# STM32H573 register map
File version: 1.7
CPU: CM33 r0p0, little endian, MPU, FPU, 4 interrupt priority bits
Registers are 32-bit, read-write, reset 0x0 unless marked. A register's access mark holds for its fields unless they carry their own. Offsets are from the block's base; [hi:lo] are bit positions; {n}, {i} and the like mark numbered series; 'fields as' and 'values as' point back to an identical list.

## TIM2 — General-purpose timers
Base 0x40000000
Same registers: SEC_TIM2 0x50000000
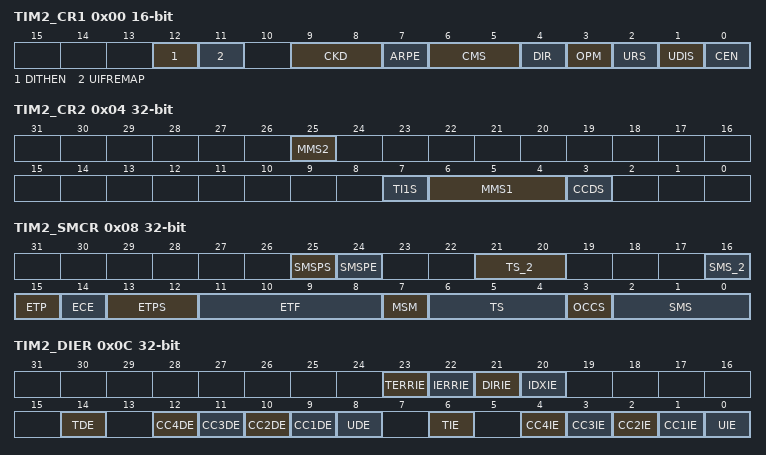
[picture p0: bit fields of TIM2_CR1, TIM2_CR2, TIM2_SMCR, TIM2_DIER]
0x00 TIM2_CR1 16-bit — TIM2 control register 1
  [12] DITHEN — Dithering Enable Note: The DITHEN bit can only be modified when CEN bit is reset.
    0=Dithering disabled; 1=Dithering enabled
  [11] UIFREMAP — UIF status bit remapping
    0=No remapping. UIF status bit is not copied to TIMx_CNT register bit 31.; 1=Remapping enabled. UIF status bit is copied to TIMx_CNT register bit 31.
  [9:8] CKD — Clock division This bit-field indicates the division ratio between the timer clock (tim_ker_ck) frequency and sampling clock used by the digital filters (tim_etr_in, tim_tix),
    0=tDTS = ttim_ker_ck; 1=tDTS = 2 ttim_ker_ck; 2=tDTS = 4 ttim_ker_ck
  [7] ARPE — Auto-reload preload enable
    0=TIMx_ARR register is not buffered; 1=TIMx_ARR register is buffered
  [6:5] CMS — Center-aligned mode selection Note: It is not allowed to switch from edge-aligned mode to center-aligned mode as long as the counter is enabled (CEN=1)
    0=Edge-aligned mode. The counter counts up or down depending on the direction bit (DIR).; 1=Center-aligned mode 1. The counter counts up and down alternatively. Output compare interrupt flags of channels configured in output (CCxS=00 in TIMx_CCMRx register) are set only when the counter is counting down.; 2=Center-aligned mode 2. The counter counts up and down alternatively. Output compare interrupt flags of channels configured in output (CCxS=00 in TIMx_CCMRx register) are set only when the counter is counting up.; 3=Center-aligned mode 3. The counter counts up and down alternatively. Output compare interrupt flags of channels configured in output (CCxS=00 in TIMx_CCMRx register) are set both when the counter is counting up or down.
  [4] DIR — Direction Note: This bit is read only when the timer is configured in Center-aligned mode or Encoder mode.
    0=Counter used as upcounter; 1=Counter used as downcounter
  [3] OPM — One-pulse mode
    0=Counter is not stopped at update event; 1=Counter stops counting at the next update event (clearing the bit CEN)
  [2] URS — Update request source This bit is set and cleared by software to select the UEV event sources. Counter overflow/underflow Setting the UG bit Update generation through the slave mode controller
    0=Any of the following events generate an update interrupt or DMA request if enabled. These events can be:; 1=Only counter overflow/underflow generates an update interrupt or DMA request if enabled
  [1] UDIS — Update disable This bit is set and cleared by software to enable/disable UEV event generation. Counter overflow/underflow Setting the UG bit Update generation through the slave mode controller Buffered registers are then loaded with their preload values.
    0=UEV enabled. The Update (UEV) event is generated by one of the following events:; 1=UEV disabled. The Update event is not generated, shadow registers keep their value (ARR, PSC, CCRx). However the counter and the prescaler are reinitialized if the UG bit is set or if a hardware reset is received from the slave mode controller.
  [0] CEN — Counter enable Note: External clock, gated mode and encoder mode can work only if the CEN bit has been previously set by software. However trigger mode can set the CEN bit automatically by hardware. CEN is cleared automatically in one-pulse mode, when an update event occurs.
    0=Counter disabled; 1=Counter enabled
0x04 TIM2_CR2 — TIM2 control register 2
  [25] MMS2 — Master mode selection These bits allow to select the information to be sent in master mode to slave timers for synchronization (tim_trgo). The combination is as follows: tim_trgo, except if the master/slave mode is selected (see the MSM bit description in TIMx_SMCR register). Others: Reserved Note: The clock of the slave timer or ADC must be enabled prior to receive events from the master timer, and must not be changed on-the-fly while triggers are received from the master timer.
    0=Reset the UG bit from the TIMx_EGR register is used as trigger output (tim_trgo). If the reset is generated by the trigger input (slave mode controller configured in reset mode) then the signal on tim_trgo is delayed compared to the actual reset.; 1=Enable the Counter enable signal, CNT_EN, is used as trigger output (tim_trgo). It is useful to start several timers at the same time or to control a window in which a slave timer is enabled. The Counter Enable signal is generated by a logic AND between CEN control bit and the trigger input when configured in gated mode.When the Counter Enable signal is controlled by the trigger input, there is a delay on
  [7] TI1S — tim_ti1 selection
    0=The tim_ti1_in[15..0] multiplexer output is to tim_ti1 input; 1=The tim_ti1_in[15..0], tim_ti2_in[15..0] and tim_ti3_in[15..0] multiplexers outputs are XORed and connected to the tim_ti1 input. See also sensors on page 1494.
  [6:4] MMS1 — Master mode selection These bits allow to select the information to be sent in master mode to slave timers for synchronization (tim_trgo). The combination is as follows: tim_trgo, except if the master/slave mode is selected (see the MSM bit description in TIMx_SMCR register). Others: Reserved Note: The clock of the slave timer or ADC must be enabled prior to receive events from the master timer, and must not be changed on-the-fly while triggers are received from the master timer.
    0=Reset the UG bit from the TIMx_EGR register is used as trigger output (tim_trgo). If the reset is generated by the trigger input (slave mode controller configured in reset mode) then the signal on tim_trgo is delayed compared to the actual reset.; 1=Enable the Counter enable signal, CNT_EN, is used as trigger output (tim_trgo). It is useful to start several timers at the same time or to control a window in which a slave timer is enabled. The Counter Enable signal is generated by a logic AND between CEN control bit and the trigger input when configured in gated mode.When the Counter Enable signal is controlled by the trigger input, there is a delay on; 2=Update The update event is selected as trigger output (tim_trgo). For instance a master timer can then be used as a prescaler for a slave timer.; 3=Compare Pulse The trigger output send a positive pulse when the CC1IF flag is to be set (even if it was already high), as soon as a capture or a compare match occurred (tim_trgo); {v}=Compare tim_oc{v-3}refc signal is used as trigger output (tim_trgo) (v=4..7)
  [3] CCDS — Capture/compare DMA selection
    0=CCx DMA request sent when CCx event occurs; 1=CCx DMA requests sent when update event occurs
0x08 TIM2_SMCR — TIM2 slave mode control register
  [25] SMSPS — SMS preload source This bit selects whether the events that triggers the SMS[3:0] bitfield transfer from preload to active
    0=The transfer is triggered by the Timer's Update event; 1=The transfer is triggered by the Index event
  [24] SMSPE — SMS preload enable This bit selects whether the SMS[3:0] bitfield is preloaded
    0=SMS[3:0] bitfield is not preloaded; 1=SMS[3:0] preload is enabled
  [21:20] TS_2 — Trigger selection (see bits 21:20 for TS[4:3]) This bit-field selects the trigger input to be used to synchronize the counter. Others: Reserved See for product specific implementation details. Note: These bits must be changed only when they are not used (e.g. when SMS=000) to avoid wrong edge detections at the transition.
    {v}=Internal trigger {v} (tim_itr{v}) (v=0..3)
  [16] SMS_2 — Slave mode selection When external signals are selected the active edge of the trigger signal (tim_trgi) is linked to the polarity selected on the external input (see Input Control register and Control Register description. Note: The gated mode must not be used if tim_ti1f_ed is selected as the trigger input (TS=00100). Indeed, tim_ti1f_ed outputs 1 pulse for each transition on tim_ti1f, whereas the gated mode checks the level of the trigger signal. Note: The clock of the slave peripherals (timer, ADC, ...) receiving the tim_trgo signal must be enabled prior to receive events from the master timer, and the clock frequency (prescaler) must not be changed on-the-fly while triggers are received from the master timer.
    0=Slave mode disabled if CEN = '1 then the prescaler is clocked directly by the internal clock; 1=Encoder mode 1 Counter counts up/down on tim_ti1fp1 edge depending on tim_ti2fp2 level
  [15] ETP — External trigger polarity This bit selects whether tim_etr_in or tim_etr_in is used for trigger operations
    0=tim_etr_in is non-inverted, active at high level or rising edge; 1=tim_etr_in is inverted, active at low level or falling edge
  [14] ECE — External clock enable This bit enables External clock mode 2. Note: Setting the ECE bit has the same effect as selecting external clock mode 1 with tim_trgi connected to tim_etrf (SMS=111 and TS=00111). It is possible to simultaneously use external clock mode 2 with the following slave modes: reset mode, gated mode and trigger mode. Nevertheless, tim_trgi must not be connected to tim_etrf in this case (TS bits must not be 00111). If external clock mode 1 and external clock mode 2 are enabled at the same time, the external clock input is tim_etrf.
    0=External clock mode 2 disabled; 1=External clock mode 2 enabled. The counter is clocked by any active edge on the tim_etrf signal.
  [13:12] ETPS — External trigger prescaler External trigger signal tim_etrp frequency must be at most 1/4 of tim_ker_ck frequency. A prescaler can be enabled to reduce tim_etrp frequency. It is useful when inputting fast external clocks on tim_etr_in.
    0=Prescaler OFF; 1=tim_etrp frequency divided by 2; 2=tim_etrp frequency divided by 4; 3=tim_etrp frequency divided by 8
  [11:8] ETF — External trigger filter This bit-field then defines the frequency used to sample tim_etrp signal and the length of the digital filter applied to tim_etrp. The digital filter is made of an event counter in which N consecutive events are needed to validate a transition on the output:
    0=No filter, sampling is done at fDTS; 1=fSAMPLING=ftim_ker_ck, N=2; 2=fSAMPLING=ftim_ker_ck, N=4; 3=fSAMPLING=ftim_ker_ck, N=8; 4=fSAMPLING=fDTS/2, N=6; 5=fSAMPLING=fDTS/2, N=8; 6=fSAMPLING=fDTS/4, N=6; 7=fSAMPLING=fDTS/4, N=8; 8=fSAMPLING=fDTS/8, N=6; 9=fSAMPLING=fDTS/8, N=8; 10=fSAMPLING=fDTS/16, N=5; 11=fSAMPLING=fDTS/16, N=6; 12=fSAMPLING=fDTS/16, N=8; 13=fSAMPLING=fDTS/32, N=5; 14=fSAMPLING=fDTS/32, N=6; 15=fSAMPLING=fDTS/32, N=8
  [7] MSM — Master/Slave mode
    0=No action; 1=The effect of an event on the trigger input (tim_trgi) is delayed to allow a perfect synchronization between the current timer and its slaves (through tim_trgo). It is useful if we want to synchronize several timers on a single external event.
  [6:4] TS — Trigger selection (see bits 21:20 for TS[4:3]) This bit-field selects the trigger input to be used to synchronize the counter. Others: Reserved See for product specific implementation details. Note: These bits must be changed only when they are not used (e.g. when SMS=000) to avoid wrong edge detections at the transition.
    {v}=Internal trigger {v} (tim_itr{v}) (v=0..3); 4=tim_ti1 edge detector (tim_ti1f_ed); 5=Filtered timer input 1 (tim_ti1fp1); 6=Filtered timer input 2 (tim_ti2fp2); 7=External trigger input (tim_etrf)
  [3] OCCS — OCREF clear selection This bit is used to select the OCREF clear source Note: If the OCREF clear selection feature is not supported, this bit is reserved and forced by hardware to '0'. .
    0=tim_ocref_clr_int is connected to the tim_ocref_clr input; 1=tim_ocref_clr_int is connected to tim_etrf
  [2:0] SMS — Slave mode selection When external signals are selected the active edge of the trigger signal (tim_trgi) is linked to the polarity selected on the external input (see Input Control register and Control Register description. Note: The gated mode must not be used if tim_ti1f_ed is selected as the trigger input (TS=00100). Indeed, tim_ti1f_ed outputs 1 pulse for each transition on tim_ti1f, whereas the gated mode checks the level of the trigger signal. Note: The clock of the slave peripherals (timer, ADC, ...) receiving the tim_trgo signal must be enabled prior to receive events from the master timer, and the clock frequency (prescaler) must not be changed on-the-fly while triggers are received from the master timer.
    0=Slave mode disabled if CEN = '1 then the prescaler is clocked directly by the internal clock; 1=Encoder mode 1 Counter counts up/down on tim_ti1fp1 edge depending on tim_ti2fp2 level; 2=Encoder mode 2 Counter counts up/down on tim_ti2fp2 edge depending on tim_ti1fp1 level; 3=Encoder mode 3 Counter counts up/down on both tim_ti1fp1 and tim_ti2fp2 edges depending on the level of the other input; 4=Reset Mode Rising edge of the selected trigger input (tim_trgi) reinitializes the counter and generates an update of the registers; 5=Gated Mode The counter clock is enabled when the trigger input (tim_trgi) is high. The counter stops (but is not reset) as soon as the trigger becomes low. Both start and stop of the counter are controlled.; 6=Trigger Mode The counter starts at a rising edge of the trigger tim_trgi (but it is not reset). Only the start of the counter is controlled.; 7=External Clock Mode 1 Rising edges of the selected trigger (tim_trgi) clock the counter
0x0C TIM2_DIER — TIM2 DMA/Interrupt enable register
  [23] TERRIE — Transition error interrupt enable
    0=Transition error interrupt disabled; 1=Transition error interrupt enabled
  [22] IERRIE — Index error interrupt enable
    0=Index error interrupt disabled; 1=Index error interrupt enabled
  [21] DIRIE — Direction change interrupt enable
    0=Direction change interrupt disabled; 1=Direction change interrupt enabled
  [20] IDXIE — Index interrupt enable
    0=Index interrupt disabled; 1=Index interrupt enabled
  [14] TDE — Trigger DMA request enable
    0=Trigger DMA request disabled; 1=Trigger DMA request enabled
  [n+8] CC{n}DE (n=1..4) — Capture/Compare {n} DMA request enable
    0=CC{n} DMA request disabled; 1=CC{n} DMA request enabled
  [8] UDE — Update DMA request enable
    0=Update DMA request disabled; 1=Update DMA request enabled
  [6] TIE — Trigger interrupt enable
    0=Trigger interrupt disabled; 1=Trigger interrupt enabled
  [n] CC{n}IE (n=1..4) — Capture/Compare {n} interrupt enable
    0=CC{n} interrupt disabled; 1=CC{n} interrupt enabled
  [0] UIE — Update interrupt enable
    0=Update interrupt disabled; 1=Update interrupt enabled
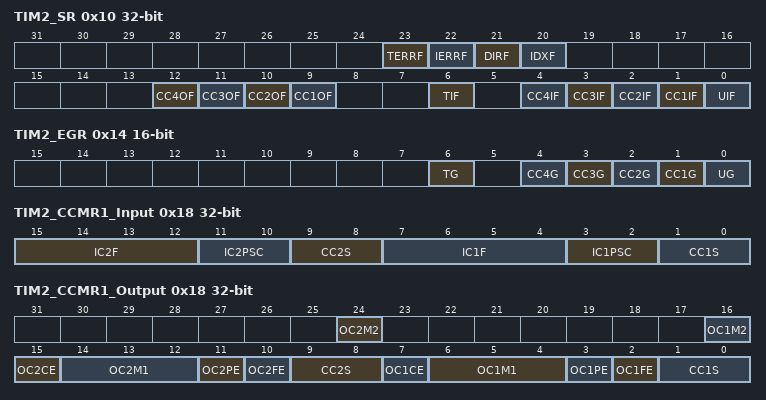
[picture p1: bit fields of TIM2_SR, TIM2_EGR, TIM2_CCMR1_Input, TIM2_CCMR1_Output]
0x10 TIM2_SR — TIM2 status register
  [23] TERRF — Transition error interrupt flag This flag is set by hardware when a transition error is detected in encoder mode. It is cleared by software by writing it to '0'.
    0=No encoder transition error has been detected; 1=An encoder transition error has been detected
  [22] IERRF — Index error interrupt flag This flag is set by hardware when an index error is detected. It is cleared by software by writing it to '0'.
    0=No index error has been detected; 1=An index error has been detected
  [21] DIRF — Direction change interrupt flag This flag is set by hardware when the direction changes in encoder mode (DIR bit value in TIMx_CR is changing). It is cleared by software by writing it to '0'.
    0=No direction change; 1=Direction change
  [20] IDXF — Index interrupt flag This flag is set by hardware when an index event is detected. It is cleared by software by writing it to '0'.
    0=No index event occurred; 1=An index event has occurred
  [12] CC4OF — Capture/Compare 4 overcapture flag refer to CC1OF description
  [11] CC3OF — Capture/Compare 3 overcapture flag refer to CC1OF description
  [10] CC2OF — Capture/compare 2 overcapture flag refer to CC1OF description
  [9] CC1OF — Capture/Compare 1 overcapture flag This flag is set by hardware only when the corresponding channel is configured in input capture mode. It is cleared by software by writing it to '0'.
    0=No overcapture has been detected; 1=The counter value has been captured in TIMx_CCR1 register while CC1IF flag was already set
  [6] TIF — Trigger interrupt flag This flag is set by hardware on the TRG trigger event (active edge detected on tim_trgi input when the slave mode controller is enabled in all modes but gated mode. It is set when the counter starts or stops when gated mode is selected. It is cleared by software.
    0=No trigger event occurred; 1=Trigger interrupt pending
  [4] CC4IF — Capture/Compare 4 interrupt flag Refer to CC1IF description
  [3] CC3IF — Capture/Compare 3 interrupt flag Refer to CC1IF description
  [2] CC2IF — Capture/Compare 2 interrupt flag Refer to CC1IF description
  [1] CC1IF — Capture/compare 1 interrupt flag This flag is set by hardware. It is cleared by software (input capture or output compare mode) or by reading the TIMx_CCR1 register (input capture mode only). If channel CC1 is configured as output: this flag is set when the content of the counter TIMx_CNT matches the content of the TIMx_CCR1 register. When the content of TIMx_CCR1 is greater than the content of TIMx_ARR, the CC1IF bit goes high on the counter overflow (in up-counting and up/down-counting modes) or underflow (in downcounting mode). There are 3 possible options for flag setting in center-aligned mode, refer to the CMS bits in the TIMx_CR1 register for the full description. If channel CC1 is configured as input: this bit is set when counter value has been captured in TIMx_CCR1 register (an edge has been detected on IC1, as per the edge sensitivity defined with the CC1P and CC1NP bits setting, in TIMx_CCER).
    0=No compare match / No input capture occurred; 1=A compare match or an input capture occurred
  [0] UIF — Update interrupt flag This bit is set by hardware on an update event. It is cleared by software. At overflow or underflow and if UDIS=0 in the TIMx_CR1 register. When CNT is reinitialized by software using the UG bit in TIMx_EGR register, if URS=0 and UDIS=0 in the TIMx_CR1 register. When CNT is reinitialized by a trigger event (refer to the synchro control register description), if URS=0 and UDIS=0 in the TIMx_CR1 register.
    0=No update occurred; 1=Update interrupt pending. This bit is set by hardware when the registers are updated:
0x14 TIM2_EGR 16-bit wo — TIM2 event generation register
  [6] TG — Trigger generation This bit is set by software in order to generate an event, it is automatically cleared by hardware.
    0=No action; 1=The TIF flag is set in TIMx_SR register. Related interrupt or DMA transfer can occur if enabled.
  [4] CC4G — Capture/compare 4 generation Refer to CC1G description
  [3] CC3G — Capture/compare 3 generation Refer to CC1G description
  [2] CC2G — Capture/compare 2 generation Refer to CC1G description
  [1] CC1G — Capture/compare 1 generation This bit is set by software in order to generate an event, it is automatically cleared by hardware. If channel CC1 is configured as output: CC1IF flag is set, Corresponding interrupt or DMA request is sent if enabled. If channel CC1 is configured as input: The current value of the counter is captured in TIMx_CCR1 register. The CC1IF flag is set, the corresponding interrupt or DMA request is sent if enabled. The CC1OF flag is set if the CC1IF flag was already high.
    0=No action; 1=A capture/compare event is generated on channel 1:
  [0] UG — Update generation This bit can be set by software, it is automatically cleared by hardware.
    0=No action; 1=Re-initialize the counter and generates an update of the registers. Note that the prescaler counter is cleared too (anyway the prescaler ratio is not affected). The counter is cleared if the center-aligned mode is selected or if DIR=0 (upcounting), else it takes the auto-reload value (TIMx_ARR) if DIR=1 (downcounting).
0x18 TIM2_CCMR1_Input — TIM2 capture/compare mode register 1 [alternate]
  [15:12] IC2F — Input capture 2 filter
  [11:10] IC2PSC — Input capture 2 prescaler
  [9:8] CC2S — Capture/compare 2 selection This bit-field defines the direction of the channel (input/output) as well as the used input. Note: CC2S bits are writable only when the channel is OFF (CC2E = 0 in TIMx_CCER).
    0=CC2 channel is configured as output; 1=CC2 channel is configured as input, tim_ic2 is mapped on tim_ti2; 2=CC2 channel is configured as input, tim_ic2 is mapped on tim_ti1; 3=CC2 channel is configured as input, tim_ic2 is mapped on tim_trc. This mode is working only if an internal trigger input is selected through TS bit (TIMx_SMCR register)
  [7:4] IC1F — Input capture 1 filter This bit-field defines the frequency used to sample tim_ti1 input and the length of the digital filter applied to tim_ti1. The digital filter is made of an event counter in which N consecutive events are needed to validate a transition on the output:
    values as TIM2_SMCR.ETF
  [3:2] IC1PSC — Input capture 1 prescaler This bit-field defines the ratio of the prescaler acting on CC1 input (tim_ic1). The prescaler is reset as soon as CC1E=0 (TIMx_CCER register).
    0=no prescaler, capture is done each time an edge is detected on the capture input; 1=capture is done once every 2 events; 2=capture is done once every 4 events; 3=capture is done once every 8 events
  [1:0] CC1S — Capture/Compare 1 selection This bit-field defines the direction of the channel (input/output) as well as the used input. Note: CC1S bits are writable only when the channel is OFF (CC1E = 0 in TIMx_CCER).
    0=CC1 channel is configured as output; 1=CC1 channel is configured as input, tim_ic1 is mapped on tim_ti1; 2=CC1 channel is configured as input, tim_ic1 is mapped on tim_ti2; 3=CC1 channel is configured as input, tim_ic1 is mapped on tim_trc. This mode is working only if an internal trigger input is selected through TS bit (TIMx_SMCR register)
0x18 TIM2_CCMR1_Output (alternate view of TIM2_CCMR1_Input) — TIM2 capture/compare mode register 1 [alternate]
  [24] OC2M2 — Output compare 2 mode refer to OC1M description on bits 6:4
  [16] OC1M2 — Output compare 1 mode These bits define the behavior of the output reference signal tim_oc1ref from which tim_oc1 is derived. tim_oc1ref is active high whereas tim_oc1 active level depends on CC1P bit. Note: In PWM mode, the tim_ocref_clr level changes only when the result of the comparison changes or when the output compare mode switches from 'frozen' mode to 'PWM' mode.
    0=Frozen The comparison between the output compare register TIMx_CCR1 and the counter TIMx_CNT has no effect on the outputs.(this mode is used to generate a timing base); 1=Set channel 1 to active level on match. tim_oc1ref signal is forced high when the counter TIMx_CNT matches the capture/compare register 1 (TIMx_CCR1).
  [15] OC2CE — Output compare 2 clear enable
  [14:12] OC2M1 — Output compare 2 mode refer to OC1M description on bits 6:4
  [11] OC2PE — Output compare 2 preload enable
  [10] OC2FE — Output compare 2 fast enable
  [9:8] CC2S — Capture/Compare 2 selection This bit-field defines the direction of the channel (input/output) as well as the used input. Note: CC2S bits are writable only when the channel is OFF (CC2E = 0 in TIMx_CCER).
    0=CC2 channel is configured as output; 1=CC2 channel is configured as input, tim_ic2 is mapped on tim_ti2; 2=CC2 channel is configured as input, tim_ic2 is mapped on tim_ti1; 3=CC2 channel is configured as input, tim_ic2 is mapped on tim_trc. This mode is working only if an internal trigger input is selected through the TS bit (TIMx_SMCR register)
  [7] OC1CE — Output compare 1 clear enable
    0=tim_oc1ref is not affected by the tim_ocref_clr_int input; 1=tim_oc1ref is cleared as soon as a High level is detected on tim_ocref_clr_int input
  [6:4] OC1M1 — Output compare 1 mode These bits define the behavior of the output reference signal tim_oc1ref from which tim_oc1 is derived. tim_oc1ref is active high whereas tim_oc1 active level depends on CC1P bit. Note: In PWM mode, the tim_ocref_clr level changes only when the result of the comparison changes or when the output compare mode switches from 'frozen' mode to 'PWM' mode.
    0=Frozen The comparison between the output compare register TIMx_CCR1 and the counter TIMx_CNT has no effect on the outputs.(this mode is used to generate a timing base); 1=Set channel 1 to active level on match. tim_oc1ref signal is forced high when the counter TIMx_CNT matches the capture/compare register 1 (TIMx_CCR1).; 2=Set channel 1 to inactive level on match. tim_oc1ref signal is forced low when the counter TIMx_CNT matches the capture/compare register 1 (TIMx_CCR1).; 3=Toggle tim_oc1ref toggles when TIMx_CNT=TIMx_CCR1; 4=Force inactive level tim_oc1ref is forced low; 5=Force active level tim_oc1ref is forced high; 6=PWM mode 1 In upcounting, channel 1 is active as long as TIMx_CNT TIMx_CCR1 else inactive. In downcounting, channel 1 is inactive (tim_oc1ref=0) as long as TIMx_CNT TIMx_CCR1 else active (tim_oc1ref=1).; 7=PWM mode 2 In upcounting, channel 1 is inactive as long as TIMx_CNT TIMx_CCR1 else active. In downcounting, channel 1 is active as long as TIMx_CNT TIMx_CCR1 else inactive.
  [3] OC1PE — Output compare 1 preload enable Note: The PWM mode can be used without validating the preload register only in one-pulse mode (OPM bit set in TIMx_CR1 register). Else the behavior is not guaranteed.
    0=Preload register on TIMx_CCR1 disabled. TIMx_CCR1 can be written at anytime, the new value is taken in account immediately.; 1=Preload register on TIMx_CCR1 enabled. Read/Write operations access the preload register. TIMx_CCR1 preload value is loaded in the active register at each update event.
  [2] OC1FE — Output compare 1 fast enable This bit decreases the latency between a trigger event and a transition on the timer output. It must be used in one-pulse mode (OPM bit set in TIMx_CR1 register), to have the output pulse starting as soon as possible after the starting trigger.
    0=CC1 behaves normally depending on counter and CCR1 values even when the trigger is ON. The minimum delay to activate CC1 output when an edge occurs on the trigger input is 5 clock cycles.; 1=An active edge on the trigger input acts like a compare match on CC1 output. Then, OC is set to the compare level independently from the result of the comparison. Delay to sample the trigger input and to activate CC1 output is reduced to 3 clock cycles. OCFE acts only if the channel is configured in PWM1 or PWM2 mode.
  [1:0] CC1S — Capture/Compare 1 selection This bit-field defines the direction of the channel (input/output) as well as the used input. Note: CC1S bits are writable only when the channel is OFF (CC1E = 0 in TIMx_CCER).
    values as TIM2_CCMR1_Input.CC1S
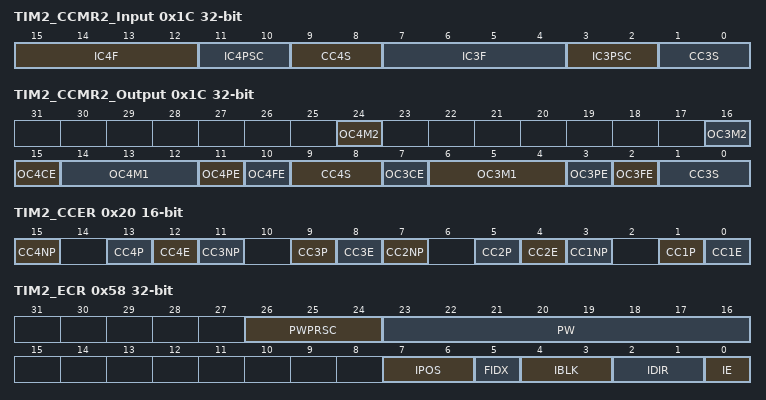
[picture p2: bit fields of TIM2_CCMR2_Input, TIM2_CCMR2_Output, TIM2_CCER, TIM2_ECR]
0x1C TIM2_CCMR2_Input — TIM2 capture/compare mode register 2 [alternate]
  [15:12] IC4F — Input capture 4 filter
  [11:10] IC4PSC — Input capture 4 prescaler
  [9:8] CC4S — Capture/Compare 4 selection This bit-field defines the direction of the channel (input/output) as well as the used input. Note: CC4S bits are writable only when the channel is OFF (CC4E = 0 in TIMx_CCER).
    0=CC4 channel is configured as output; 1=CC4 channel is configured as input, tim_ic4 is mapped on tim_ti4; 2=CC4 channel is configured as input, tim_ic4 is mapped on tim_ti3; 3=CC4 channel is configured as input, tim_ic4 is mapped on tim_trc. This mode is working only if an internal trigger input is selected through TS bit (TIMx_SMCR register)
  [7:4] IC3F — Input capture 3 filter
  [3:2] IC3PSC — Input capture 3 prescaler
  [1:0] CC3S — Capture/Compare 3 selection This bit-field defines the direction of the channel (input/output) as well as the used input. Note: CC3S bits are writable only when the channel is OFF (CC3E = 0 in TIMx_CCER).
    0=CC3 channel is configured as output; 1=CC3 channel is configured as input, tim_ic3 is mapped on tim_ti3; 2=CC3 channel is configured as input, tim_ic3 is mapped on tim_ti4; 3=CC3 channel is configured as input, tim_ic3 is mapped on tim_trc. This mode is working only if an internal trigger input is selected through TS bit (TIMx_SMCR register)
0x1C TIM2_CCMR2_Output (alternate view of TIM2_CCMR2_Input) — TIM2 capture/compare mode register 2 [alternate]
  [24] OC4M2 — Output compare 4 mode Refer to OC1M description (bits 6:4 in TIMx_CCMR1 register)
  [16] OC3M2 — Output compare 3 mode Refer to OC1M description (bits 6:4 in TIMx_CCMR1 register)
  [15] OC4CE — Output compare 4 clear enable
  [14:12] OC4M1 — Output compare 4 mode Refer to OC1M description (bits 6:4 in TIMx_CCMR1 register)
  [11] OC4PE — Output compare 4 preload enable
  [10] OC4FE — Output compare 4 fast enable
  [9:8] CC4S — Capture/Compare 4 selection This bit-field defines the direction of the channel (input/output) as well as the used input. Note: CC4S bits are writable only when the channel is OFF (CC4E = 0 in TIMx_CCER).
    values as TIM2_CCMR2_Input.CC4S
  [7] OC3CE — Output compare 3 clear enable
  [6:4] OC3M1 — Output compare 3 mode Refer to OC1M description (bits 6:4 in TIMx_CCMR1 register)
  [3] OC3PE — Output compare 3 preload enable
  [2] OC3FE — Output compare 3 fast enable
  [1:0] CC3S — Capture/Compare 3 selection This bit-field defines the direction of the channel (input/output) as well as the used input. Note: CC3S bits are writable only when the channel is OFF (CC3E = 0 in TIMx_CCER).
    values as TIM2_CCMR2_Input.CC3S
0x20 TIM2_CCER 16-bit — TIM2 capture/compare enable register
  [15] CC4NP — Capture/Compare 4 output Polarity. Refer to CC1NP description
  [13] CC4P — Capture/Compare 4 output Polarity. Refer to CC1P description
  [12] CC4E — Capture/Compare 4 output enable. refer to CC1E description
  [11] CC3NP — Capture/Compare 3 output Polarity. Refer to CC1NP description
  [9] CC3P — Capture/Compare 3 output Polarity. Refer to CC1P description
  [8] CC3E — Capture/Compare 3 output enable. Refer to CC1E description
  [7] CC2NP — Capture/Compare 2 output Polarity. Refer to CC1NP description
  [5] CC2P — Capture/Compare 2 output Polarity. refer to CC1P description
  [4] CC2E — Capture/Compare 2 output enable. Refer to CC1E description
  [3] CC1NP — Capture/Compare 1 output Polarity. CC1 channel configured as output: CC1NP must be kept cleared in this case. CC1 channel configured as input: This bit is used in conjunction with CC1P to define tim_ti1fp1/tim_ti2fp1 polarity. refer to CC1P description.
  [1] CC1P — Capture/Compare 1 output Polarity. When CC1 channel is configured as input, both CC1NP/CC1P bits select the active polarity of TI1FP1 and TI2FP1 for trigger or capture operations. CC1NP=0, CC1P=0: non-inverted/rising edge. The circuit is sensitive to TIxFP1 rising edge (capture or trigger operations in reset, external clock or trigger mode), TIxFP1 is not inverted (trigger operation in gated mode or encoder mode). CC1NP=0, CC1P=1: inverted/falling edge. The circuit is sensitive to TIxFP1 falling edge (capture or trigger operations in reset, external clock or trigger mode), TIxFP1 is inverted (trigger operation in gated mode or encoder mode). CC1NP=1, CC1P=1: non-inverted/both edges. The circuit is sensitive to both TIxFP1 rising and falling edges (capture or trigger operations in reset, external clock or trigger mode), TIxFP1is not inverted (trigger operation in gated mode). This configuration must not be used in encoder mode. CC1NP=1, CC1P=0: this configuration is reserved, it must not be used.
    0=OC1 active high (output mode) / Edge sensitivity selection (input mode, see below); 1=OC1 active low (output mode) / Edge sensitivity selection (input mode, see below)
  [0] CC1E — Capture/Compare 1 output enable.
    0=Capture mode disabled / OC1 is not active; 1=Capture mode enabled / OC1 signal is output on the corresponding output pin
0x24 TIM2_CNT — TIM2 counter
  [31:0] CNT — or UIFCPY: Value depends on IUFREMAP in TIMx_CR1. If UIFREMAP = 0 nullMost significant bit of counter value If UIFREMAP = 1 UIFCPY: UIF Copy This bit is a read-only copy of the UIF bit of the TIMx_ISR register nullLeast significant part of counter value Non-dithering mode (DITHEN = 0) The register holds the counter value. Dithering mode (DITHEN = 1) The register holds the non-dithered part in CNT[30:0]. The fractional part is not available.
0x28 TIM2_PSC 16-bit — TIM2 prescaler
  [15:0] PSC — Prescaler value The counter clock frequency tim_cnt_ck is equal to ftim_psc_ck / (PSC[15:0] + 1). PSC contains the value to be loaded in the active prescaler register at each update event (including when the counter is cleared through UG bit of TIMx_EGR register or through trigger controller when configured in 'reset mode').
0x2C TIM2_ARR reset 0xFFFFFFFF — TIM2 auto-reload register
  [31:0] ARR — Auto-reload value ARR is the value to be loaded in the actual auto-reload register. Refer to the for more details about ARR update and behavior. The counter is blocked while the auto-reload value is null. Non-dithering mode (DITHEN = 0) The register holds the auto-reload value. Dithering mode (DITHEN = 1) The register holds the integer part in ARR[31:4]. The ARR[3:0] bitfield contains the dithered part.
{0x30+4i} TIM2_CCR{i} (i=1..4) — TIM2 capture/compare register {i}
  [31:0] CCR{i} — Capture/compare {i} value If channel CC{i} is configured as output: CCR{i} is the value to be loaded in the actual capture/compare {i} register (preload value). It is loaded permanently if the preload feature is not selected in the TIMx_CCMR{i} register (bit OC{i}PE). Else the preload value is copied in the active capture/compare {i} register when an update event occurs. The active capture/compare register contains the value to be compared to the counter TIMx_CNT and signaled on tim_oc{i} output. Non-dithering mode (DITHEN = 0) The register holds the compare value. Dithering mode (DITHEN = 1) The register holds the integer part in CCR{i}[31:4]. The CCR{i}[3:0] bitfield contains the dithered part. If channel CC{i} is configured as input: CCR{i} is the counter value transferred by the last input capture {i} event (tim_ic{i}). The TIMx_CCR{i} register is read-only and cannot be programmed. Non-dithering mode (DITHEN = 0) The register holds the capture value. Dithering mode (DITHEN = 1) The register holds the capture in CCR{i}[31:0]. The CCR{i}[3:0] bits are reset.
0x58 TIM2_ECR — TIM2 timer encoder control register
  [26:24] PWPRSC — Pulse width prescaler This bitfield sets the clock prescaler for the pulse generator, as following: tPWG = (2(PWPRSC[2:0])) x ttim_ker_ck
  [23:16] PW — Pulse width This bitfield defines the pulse duration, as following: tPW = PW[7:0] x tPWG
  [7:6] IPOS — Index positioning In quadrature encoder mode (SMS[3:0] = 0001, 0010, 0011, 1110, 1111), this bit indicates in which AB input configuration the Index event resets the counter. In directional clock mode or clock plus direction mode (SMS[3:0] = 1010, 1011, 1100, 1101), these bits indicates on which level the Index event resets the counter. In bidirectional clock mode, this applies for both clock inputs. x0: Index resets the counter when clock is 0 x1: Index resets the counter when clock is 1 Note: IPOS[1] bit is not significant
    0=Index resets the counter when AB = 00; 1=Index resets the counter when AB = 01; 2=Index resets the counter when AB = 10; 3=Index resets the counter when AB = 11
  [5] FIDX — First index This bit indicates if the first index only is taken into account
    0=Index is always active; 1=the first Index only resets the counter
  [4:3] IBLK — Index blanking This bit indicates if the Index event is conditioned by the tim_ti3 input
    0=Index always active; 1=Index disabled hen tim_ti3 input is active, as per CC3P bitfield; 2=Index disabled when tim_ti4 input is active, as per CC4P bitfield
  [2:1] IDIR — Index direction This bit indicates in which direction the Index event resets the counter. Note: The IDR[1:0] bitfield must be written when IE bit is reset (index disabled).
    0=Index resets the counter whatever the direction; 1=Index resets the counter when up-counting only; 2=Index resets the counter when down-counting only
  [0] IE — Index enable This bit indicates if the Index event resets the counter.
    0=Index disabled; 1=Index enabled
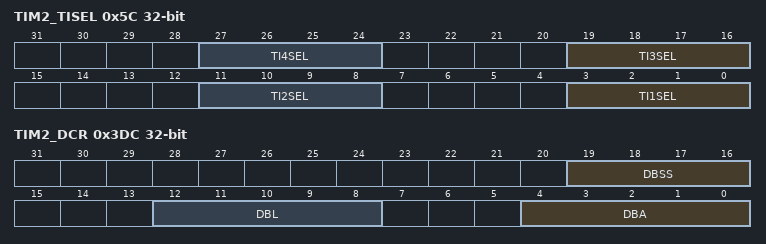
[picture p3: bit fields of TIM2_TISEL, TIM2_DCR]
0x5C TIM2_TISEL — TIM2 timer input selection register
  [8n-5:8n-8] TI{n}SEL (n=1..4) — Selects tim_ti{n}[0..15] input ... Refer to for product specific implementation.
    0=tim_ti{n}_in0: TIMx_CH{n}; 1=tim_ti{n}_in1; 15=tim_ti{n}_in15
0x60 TIM2_AF1 — TIM2 alternate function register 1
  [17:14] ETRSEL — etr_in source selection These bits select the etr_in input source. ... Refer to for product specific implementation.
    0=tim_etr0: TIMx_ETR input; 1=tim_etr1; 15=tim_etr15
0x64 TIM2_AF2 — TIM2 alternate function register 2
  [18:16] OCRSEL — ocref_clr source selection These bits select the ocref_clr input source. ... Refer to for product specific implementation.
    0=tim_ocref_clr0; 1=tim_ocref_clr1; 7=tim_ocref_clr7
0x3DC TIM2_DCR — TIM2 DMA control register
  [19:16] DBSS — DMA burst source selection This bitfield defines the interrupt source that triggers the DMA burst transfers (the timer recognizes a burst transfer when a read or a write access is done to the TIMx_DMAR address). Others: reserved
    1=Update; {v}=CC{v-1} (v=2..5); 6=COM; 7=Trigger
  [12:8] DBL — DMA burst length This 5-bit vector defines the length of DMA transfers (the timer recognizes a burst transfer when a read or a write access is done to the TIMx_DMAR address), i.e. the number of transfers. Transfers can be in half-words or in bytes (see example below). ... Example: Let us consider the following transfer: DBL = 7 bytes & DBA = TIM2_CR1. If DBL = 7 bytes and DBA = TIM2_CR1 represents the address of the byte to be transferred, the address of the transfer should be given by the following equation: (TIMx_CR1 address) + DBA + (DMA index), where DMA index = DBL In this example, 7 bytes are added to (TIMx_CR1 address) + DBA, which gives us the address from/to which the data are copied. In this case, the transfer is done to 7 registers starting from the following address: (TIMx_CR1 address) + DBA According to the configuration of the DMA Data Size, several cases may occur: If the DMA Data Size is configured in half-words, 16-bit data are transferred to each of the 7 registers. If the DMA Data Size is configured in bytes, the data are also transferred to 7 registers: the first register contains the first MSB byte, the second register, the first LSB byte and so on. So with the transfer Timer, one also has to specify the size of data transferred by DMA.
    0=1 transfer; 1=2 transfers; 2=3 transfers; 26=26 transfers
  [4:0] DBA — DMA base address This 5-bits vector defines the base-address for DMA transfers (when read/write access are done through the TIMx_DMAR address). DBA is defined as an offset starting from the address of the TIMx_CR1 register. Example: ...
    0=TIMx_CR1,; 1=TIMx_CR2,; 2=TIMx_SMCR,
0x3E0 TIM2_DMAR — TIM2 DMA address for full transfer
  [31:0] DMAB — DMA register for burst accesses A read or write operation to the DMAR register accesses the register located at the address (TIMx_CR1 address) + (DBA + DMA index) x 4 where TIMx_CR1 address is the address of the control register 1, DBA is the DMA base address configured in TIMx_DCR register, DMA index is automatically controlled by the DMA transfer, and ranges from 0 to DBL (DBL configured in TIMx_DCR).

## TIM3 — General-purpose timers
Base 0x40000400
Same registers: SEC_TIM3 0x50000400
Registers as TIM2 (with TIM2 read as TIM3); these are added or differ:
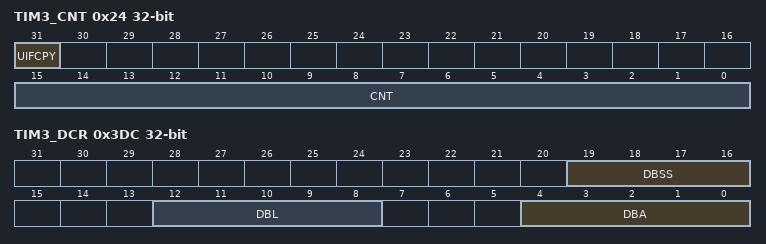
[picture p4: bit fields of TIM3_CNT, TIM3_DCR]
0x24 TIM3_CNT — TIM3 counter
  [31] UIFCPY — Value depends on IUFREMAP in TIMx_CR1. If UIFREMAP = 0 Reserved If UIFREMAP = 1 UIFCPY: UIF Copy This bit is a read-only copy of the UIF bit of the TIMx_ISR register
  [15:0] CNT — Counter value' Non-dithering mode (DITHEN = 0) The register holds the counter value. Dithering mode (DITHEN = 1) The register holds the non-dithered part in CNT[15:0]. The fractional part is not available.
0x2C TIM3_ARR reset 0xFFFFFFFF — TIM3 auto-reload register
  [19:0] ARR — Low Auto-reload value ARR is the value to be loaded in the actual auto-reload register. Refer to the for more details about ARR update and behavior. The counter is blocked while the auto-reload value is null. Non-dithering mode (DITHEN = 0) The register holds the auto-reload value. Dithering mode (DITHEN = 1) The register holds the integer part in ARR[19:4]. The ARR[3:0] bitfield contains the dithered part.
0x34 TIM3_CCR1 — TIM3 capture/compare register 1
  [19:0] CCR1 — Capture/compare 1 value If channel CC1 is configured as output: CCR1 is the value to be loaded in the actual capture/compare 1 register (preload value). It is loaded permanently if the preload feature is not selected in the TIMx_CCMR1 register (bit OC1PE). Else the preload value is copied in the active capture/compare 1 register when an update event occurs. The active capture/compare register contains the value to be compared to the counter TIMx_CNT and signaled on tim_oc1 output. Non-dithering mode (DITHEN = 0) The register holds the compare value in CCR1[15:0]. The CCR1[19:16] bits are reset. Dithering mode (DITHEN = 1) The register holds the integer part in CCR1[19:4]. The CCR1[3:0] bitfield contains the dithered part. If channel CC1 is configured as input: CCR1 is the counter value transferred by the last input capture 1 event (tim_ic1). The TIMx_CCR1 register is read-only and cannot be programmed. Non-dithering mode (DITHEN = 0) The CCR1[15:0] bits hold the capture value. The CCR1[19:16] bits are reserved. Dithering mode (DITHEN = 1) The register holds the capture in CCR1[19:0]. The CCR1[3:0] bits are reset.
0x38 TIM3_CCR2 — TIM3 capture/compare register 2
  [19:0] CCR2 — Capture/compare 1 value If channel CC2 is configured as output: CCR2 is the value to be loaded in the actual capture/compare 2 register (preload value). It is loaded permanently if the preload feature is not selected in the TIMx_CCMR2 register (bit OC2PE). Else the preload value is copied in the active capture/compare 2 register when an update event occurs. The active capture/compare register contains the value to be compared to the counter TIMx_CNT and signaled on tim_oc2 output. Non-dithering mode (DITHEN = 0) The register holds the compare value in CCR2[15:0]. The CCR2[19:16] bits are reset. Dithering mode (DITHEN = 1) The register holds the integer part in CCR2[19:4]. The CCR2[3:0] bitfield contains the dithered part. If channel CC2 is configured as input: CCR2 is the counter value transferred by the last input capture 2 event (tim_ic2). The TIMx_CCR2 register is read-only and cannot be programmed. Non-dithering mode (DITHEN = 0) The CCR2[15:0] bits hold the capture value. The CCR2[19:16] bits are reserved. Dithering mode (DITHEN = 1) The register holds the capture in CCR2[19:0]. The CCR2[3:0] bits are reset.
0x3C TIM3_CCR3 — TIM3 capture/compare register 3
  [19:0] CCR3 — Capture/compare 3 value If channel CC3 is configured as output: CCR3 is the value to be loaded in the actual capture/compare 3 register (preload value). It is loaded permanently if the preload feature is not selected in the TIMx_CCMR3 register (bit OC3PE). Else the preload value is copied in the active capture/compare 3 register when an update event occurs. The active capture/compare register contains the value to be compared to the counter TIMx_CNT and signaled on tim_oc3 output. Non-dithering mode (DITHEN = 0) The register holds the compare value in CCR3[15:0]. The CCR3[19:16] bits are reset. Dithering mode (DITHEN = 1) The register holds the integer part in CCR3[19:4]. The CCR3[3:0] bitfield contains the dithered part. If channel CC3 is configured as input: CCR3 is the counter value transferred by the last input capture 3 event (tim_ic3). The TIMx_CCR3 register is read-only and cannot be programmed. Non-dithering mode (DITHEN = 0) The CCR3[15:0] bits hold the capture value. The CCR3[19:16] bits are reserved. Dithering mode (DITHEN = 1) The register holds the capture in CCR3[19:0]. The CCR3[3:0] bits are reset.
0x40 TIM3_CCR4 — TIM3 capture/compare register 4
  [19:0] CCR4 — Capture/compare 4 value If channel CC4 is configured as output: CCR4 is the value to be loaded in the actual capture/compare 4 register (preload value). It is loaded permanently if the preload feature is not selected in the TIMx_CCMR4 register (bit OC4PE). Else the preload value is copied in the active capture/compare 4 register when an update event occurs. The active capture/compare register contains the value to be compared to the counter TIMx_CNT and signaled on tim_oc4 output. Non-dithering mode (DITHEN = 0) The register holds the compare value in CCR4[15:0]. The CCR4[19:16] bits are reset. Dithering mode (DITHEN = 1) The register holds the integer part in CCR4[19:4]. The CCR4[3:0] bitfield contains the dithered part. If channel CC4 is configured as input: CCR4 is the counter value transferred by the last input capture 4 event (tim_ic4). The TIMx_CCR4 register is read-only and cannot be programmed. Non-dithering mode (DITHEN = 0) The CCR4[15:0] bits hold the capture value. The CCR4[19:16] bits are reserved. Dithering mode (DITHEN = 1) The register holds the capture in CCR4[19:0]. The CCR4[3:0] bits are reset.
0x3DC TIM3_DCR — TIM3 DMA control register
  fields as TIM2.TIM2_DCR

## TIM4 — General-purpose timers
Base 0x40000800
Same registers: SEC_TIM4 0x50000800
Registers as TIM3 (with TIM3 read as TIM4).

## TIM5 — General-purpose timers
Base 0x40000C00
Same registers: SEC_TIM5 0x50000C00
Registers as TIM2 (with TIM2 read as TIM5); these are added or differ:
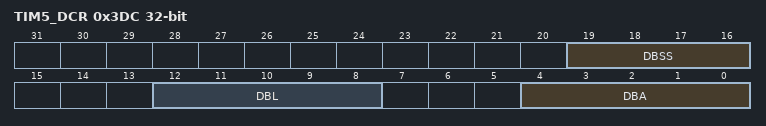
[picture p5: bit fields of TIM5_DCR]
0x3DC TIM5_DCR — TIM5 DMA control register
  fields as TIM2.TIM2_DCR
